# FM33A0XXER register map
File version: 1.0
CPU: SC000, little endian, no MPU, no FPU, 3 interrupt priority bits
Registers are 32-bit, read-write, reset 0x0 unless marked. A register's access mark holds for its fields unless they carry their own. Offsets are from the block's base; [hi:lo] are bit positions; {n}, {i} and the like mark numbered series.

## QSPI — QSPI module information
Base 0x40000800
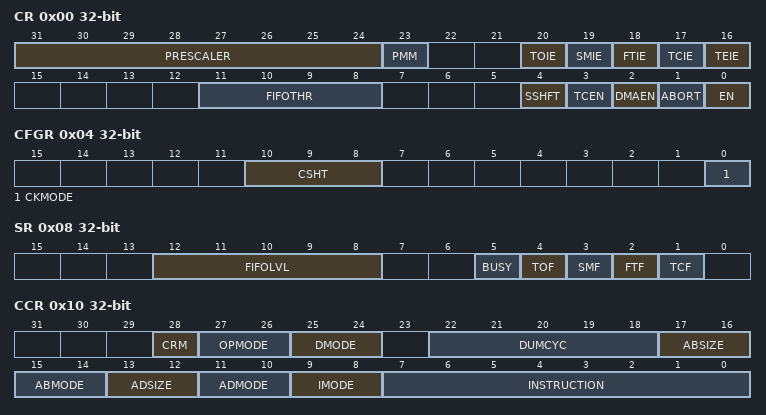
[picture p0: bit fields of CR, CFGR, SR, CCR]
0x00 CR — QSPI Control Register
  [31:24] PRESCALER — PRESCALER field description
  [23] PMM — PMM field description
  [20] TOIE — TOIE field description
  [19] SMIE — SMIE field description
  [18] FTIE — FTIE field description
  [17] TCIE — TCIE field description
  [16] TEIE — TEIE field description
  [11:8] FIFOTHR — FIFOTHR field description
  [4] SSHFT — SSHFT field description
  [3] TCEN — TCEN field description
  [2] DMAEN — DMAEN field description
  [1] ABORT — ABORT field description
  [0] EN — EN field description
0x04 CFGR — QSPI Config Register
  [10:8] CSHT — CSHT field description
  [0] CKMODE — CKMODE field description
0x08 SR — QSPI Status Register
  [12:8] FIFOLVL ro — FIFOLVL field description
  [5] BUSY ro — BUSY field description
  [4] TOF — TOF field description
  [3] SMF — SMF field description
  [2] FTF ro — FTF field description
  [1] TCF — TCF field description
0x0C DATALEN — QSPI Data Length Register
  [31:0] QSPI_DATALEN — QSPI_DATALEN field description
0x10 CCR — QSPI Communication Config Register
  [28] CRM — CRM field description
  [27:26] OPMODE — OPMODE field description
  [25:24] DMODE — DMODE field description
  [22:18] DUMCYC — DUMCYC field description
  [17:16] ABSIZE — ABSIZE field description
  [15:14] ABMODE — ABMODE field description
  [13:12] ADSIZE — ADSIZE field description
  [11:10] ADMODE — ADMODE field description
  [9:8] IMODE — IMODE field description
  [7:0] INSTRUCTION — INSTRUCTION field description
0x14 ADDR — QSPI Address Register
  [31:0] QSPI_ADDR — QSPI_ADDR field description
0x18 ABR — QSPI Alternate Bytes Register
  [31:0] QSPI_ABR — QSPI_ABR field description
0x1C DR — QSPI Data Register
  [31:0] QSPI_DATA — QSPI_DATA field description
0x20 SMSK — QSPI Status Mask Register
  [31:0] QSPI_SMSK — QSPI_SMSK field description
0x24 SMAT — QSPI Status Match Register
  [31:0] QSPI_SMAT — QSPI_SMAT field description
0x28 PITV — QSPI Polling Interval Register
  [15:0] QSPI_PITV — QSPI_PITV field description
0x2C TO — QSPI Time Out Register
  [15:0] QSPI_TO — QSPI_TO field description

## DMA — DMA module information
Base 0x40000400
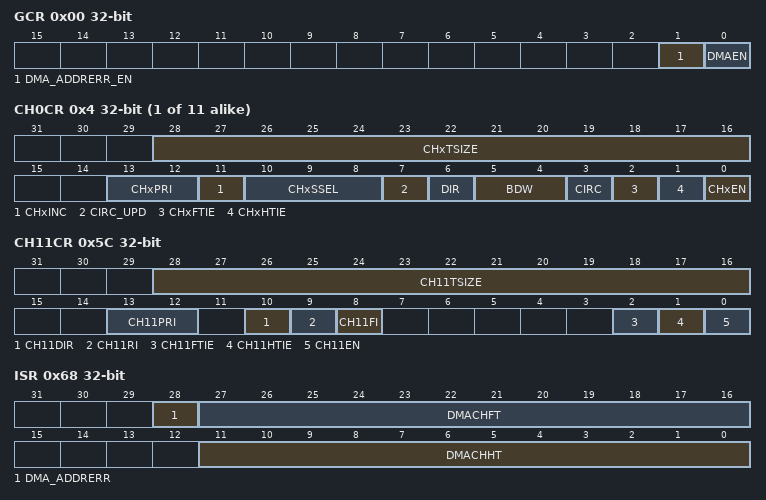
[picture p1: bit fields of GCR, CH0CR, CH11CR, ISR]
0x00 GCR — DMA Global Control Register
  [1] DMA_ADDRERR_EN — DMA_ADDRERR_EN field description
  [0] DMAEN — DMAEN field description
{0x4+8i} CH{i}CR (i=0..10) — Channel {i} Control Register
  [28:16] CHxTSIZE — CHxTSIZE field description
  [13:12] CHxPRI — CHxPRI field description
  [11] CHxINC — CHxINC field description
  [10:8] CHxSSEL — CHxSSEL field description
  [7] CIRC_UPD — CIRC_UPD field description
  [6] DIR — DIR field description
  [5:4] BDW — BDW field description
  [3] CIRC — CIRC field description
  [2] CHxFTIE — CHxFTIE field description
  [1] CHxHTIE — CHxHTIE field description
  [0] CHxEN — CHxEN field description
{0x8+8i} CH{i}MAR (i=0..5) — Channel {i} Memory Address Register
  [31:0] CHxMEMAD — CHxMEMAD field description
{0x8+8i} CH{i}MAR (i=7..10) — Channel {i} Memory Address Register
  [31:0] CHxMEMAD — CHxMEMAD field description
0x5C CH11CR — Channel 11 Control Register
  [28:16] CH11TSIZE — CH11TSIZE field description
  [13:12] CH11PRI — CH11PRI field description
  [10] CH11DIR — CH11DIR field description
  [9] CH11RI — CH11RI field description
  [8] CH11FI — CH11FI field description
  [2] CH11FTIE — CH11FTIE field description
  [1] CH11HTIE — CH11HTIE field description
  [0] CH11EN — CH11EN field description
0x60 CH11FAR — Channel 11 Flash Address Register
  [14:0] CH11FLSAD — CH11FLSAD field description
0x64 CH11RAR — Channel 11 RAM Address Register
  [14:0] CH7RAMAD — CH7RAMAD field description
0x68 ISR — DMA Interrupt Status Register
  [28] DMA_ADDRERR — DMA_ADDRERR field description
  [27:16] DMACHFT — DMACHFT field description
  [11:0] DMACHHT — DMACHHT field description
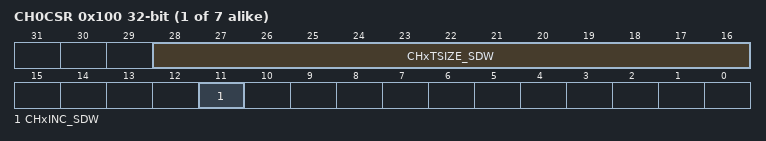
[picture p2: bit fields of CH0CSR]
{0x100+8i} CH{i}CSR (i=0..6) — Channel 0 Control Shadow Register
  [28:16] CHxTSIZE_SDW — CHxTSIZE_SDW field description
  [11] CHxINC_SDW — CHxINC_SDW field description
{0x104+8i} CH{i}MASR (i=0..6) — Channel 0 Memory Address Shadow Register
  [31:0] CHxMAD_SDW — CHxMAD_SDW field description
